# PRU_ICSS_CFG register map
Vendor: Texas Instruments
Peripheral module from a debugger description file (folder am437x).
Registers are 32-bit, access per field, no defined reset value unless marked. A register's access mark holds for its fields unless they carry their own. Offsets are as the file gives them; lines under a group give offsets from that group; [hi:lo] are bit positions; {n}, {i} and the like mark numbered series; 'fields as' and 'values as' point back to an identical list; <NAME> marks a mode.

## PRU_ICSS_CFG
0x00 PRU_ICSS_CFG_REVID ro — The Revision Register contains the ID and revision information.
  [31:0] REVID — Revision ID. Reset value for PRU-ICSS1 is 0x4700_0200 and for PRU-ICSS0 is 0x4701_0100.
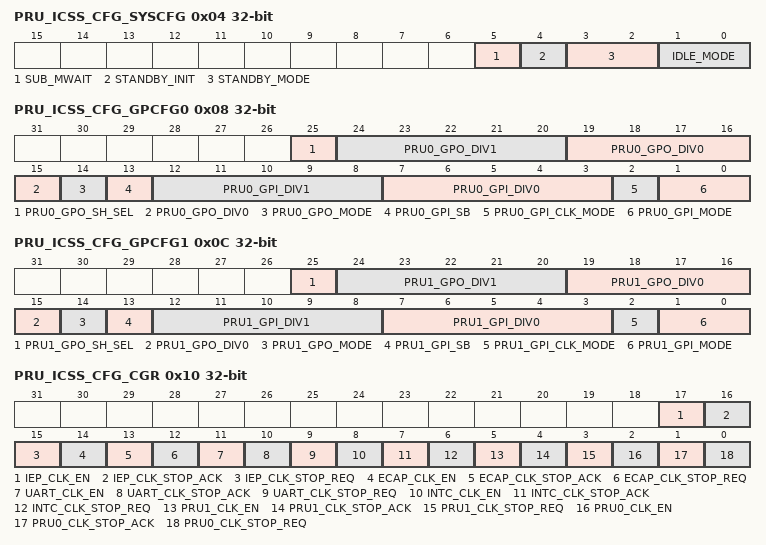
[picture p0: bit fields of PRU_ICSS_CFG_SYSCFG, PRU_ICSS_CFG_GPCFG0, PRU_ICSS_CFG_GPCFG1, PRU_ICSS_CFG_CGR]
0x04 PRU_ICSS_CFG_SYSCFG — The System Configuration Register defines the power IDLE and STANDBY modes. Note this register is only available for PRU-ICSS1. In PRU-ICSS0, it is reserved.
  [5] SUB_MWAIT ro — Status bit for wait state.
    1=en_2_0x1 (Wait until 0); 0=en_1_0x0 (Ready for Transaction)
  [4] STANDBY_INIT rw
    1=en_2_0x1 (Initiate standby sequence); 0=en_1_0x0 (Enable OCP master ports)
  [3:2] STANDBY_MODE rw
    3=en_4_0x3 (Reserved.); 2=en_3_0x2 (Smart standby mode: Standby requested by initiator depending on internal conditions.); 1=en_2_0x1 (No standby mode: Initiator unconditionally out of standby (standby = 0).); 0=en_1_0x0 (Force standby mode: Initiator unconditionally in standby (standby = 1).)
  [1:0] IDLE_MODE rw
    3=en_4_0x3 (Reserved.); 2=en_3_0x2 (Smart-idle mode.); 1=en_2_0x1 (No-idle mode.); 0=en_1_0x0 (Force-idle mode.)
0x08 PRU_ICSS_CFG_GPCFG0 — The General Purpose Configuration 0 Register defines the GPI/O configuration for PRU0.
  [25] PRU0_GPO_SH_SEL ro — Defines which shadow register is currently getting used for GPO shifting.
    1=en_2_0x1 (gpo_sh1 is selected); 0=en_1_0x0 (gpo_sh0 is selected)
  [24:20] PRU0_GPO_DIV1 rw — Divisor value (divide by PRU0_GPO_DIV1 + 1). 0h = div 1.0. 1h = div 1.5. 2h = div 2.0. .. 1eh = div 16.0. 1fh = reserved.
  [19:15] PRU0_GPO_DIV0 rw — Divisor value (divide by PRU0_GPO_DIV0 + 1). 0h = div 1.0. 1h = div 1.5. 2h = div 2.0. .. 1eh = div 16.0. 1fh = reserved.
  [14] PRU0_GPO_MODE rw
    1=en_2_0x1 (Serial output mode); 0=en_1_0x0 (Direct output mode)
  [13] PRU0_GPI_SB rw — Start Bit event for 28-bit shift mode. PRU0_GPI_SB (pru0_r31_status[29]) is set when first capture of a 1 on pru0_r31_status[0].
    1=en_4_0x1 (Will clear PRU0_GPI_SB and clear the whole shift register.); 1=en_3_0x1 (Start Bit event occurred.); 0=en_2_0x0 (No Effect.); 0=en_1_0x0 (Start Bit event has not occurred.)
  [12:8] PRU0_GPI_DIV1 rw — Divisor value (divide by PRU0_GPI_DIV1 + 1). 0h = div 1.0. 1h = div 1.5. 2h = div 2.0. .. 1eh = div 16.0. 1fh = reserved.
  [7:3] PRU0_GPI_DIV0 rw — Divisor value (divide by PRU0_GPI_DIV0 + 1). 0h = div 1.0. 1h = div 1.5. 2h = div 2.0. .. 1eh = div 16.0. 1fh = reserved.
  [2] PRU0_GPI_CLK_MODE rw — Parallel 16bit capture mode clock edge.
    1=en_2_0x1 (Use the negative edge of pru0_r31_status[16]); 0=en_1_0x0 (Use the positive edge of pru0_r31_status[16])
  [1:0] PRU0_GPI_MODE rw
0x0C PRU_ICSS_CFG_GPCFG1 — The General Purpose Configuration 1 Register defines the GPI/O configuration for PRU1.
  [25] PRU1_GPO_SH_SEL ro — Defines which shadow register is currently getting used for GPO shifting.
    values as PRU_ICSS_CFG_GPCFG0.PRU0_GPO_SH_SEL
  [24:20] PRU1_GPO_DIV1 rw — Divisor value (divide by PRU1_GPO_DIV1 + 1). 0h = div 1.0. 1h = div 1.5. 2h = div 2.0. .. 1eh = div 16.0. 1fh = reserved.
  [19:15] PRU1_GPO_DIV0 rw — Divisor value (divide by PRU1_GPO_DIV0 + 1). 0h = div 1.0. 1h = div 1.5. 2h = div 2.0. .. 1eh = div 16.0. 1fh = reserved.
  [14] PRU1_GPO_MODE rw
    values as PRU_ICSS_CFG_GPCFG0.PRU0_GPO_MODE
  [13] PRU1_GPI_SB rw — 28-bit shift mode Start Bit event. PRU1_GPI_SB (pru1_r31_status[29]) is set when first capture of a 1 on pru1_r31_status[0].
    1=en_4_0x1 (Will clear PRU1_GPI_SB and clear the whole shift register.); 1=en_3_0x1 (Start Bit event occurred.); 0=en_2_0x0 (No Effect.); 0=en_1_0x0 (Start Bit event has not occurred.)
  [12:8] PRU1_GPI_DIV1 rw — Divisor value (divide by PRU1_GPI_DIV1 + 1). 0h = div 1.0. 1h = div 1.5. 2h = div 2.0. .. 1eh = div 16.0. 1fh = reserved.
  [7:3] PRU1_GPI_DIV0 rw — Divisor value (divide by PRU1_GPI_DIV0 + 1). 0h = div 1.0. 1h = div 1.5. 2h = div 2.0. .. 1eh = div 16.0. 1fh = reserved.
  [2] PRU1_GPI_CLK_MODE rw — Parallel 16bit capture mode clock edge.
    1=en_2_0x1 (Use the negative edge of pru1_r31_status[16]); 0=en_1_0x0 (Use the positive edge of pru1_r31_status[16])
  [1:0] PRU1_GPI_MODE rw
0x10 PRU_ICSS_CFG_CGR — The Clock Gating Register controls the state of Clock Management of the different modules. Software should not clear {module}_CLK_EN until {module}_CLK_STOP_ACK is 0x1.
  [17] IEP_CLK_EN rw — IEP clock enable.
    1=en_2_0x1 (Enable Clock); 0=en_1_0x0 (Disable Clock)
  [16] IEP_CLK_STOP_ACK ro — Acknowledgement that IEP clock can be stopped.
    1=en_2_0x1 (Ready to Gate Clock); 0=en_1_0x0 (Not Ready to Gate Clock)
  [15] IEP_CLK_STOP_REQ rw — IEP request to stop clock.
    1=en_2_0x1 (Request to stop Clock); 0=en_1_0x0 (Do not request to stop Clock)
  [14] ECAP_CLK_EN rw — ECAP clock enable.
    1=en_2_0x1 (Enable Clock); 0=en_1_0x0 (Disable Clock)
  [13] ECAP_CLK_STOP_ACK ro — Acknowledgement that ECAP clock can be stopped.
    values as IEP_CLK_STOP_ACK
  [12] ECAP_CLK_STOP_REQ rw — ECAP request to stop clock.
    values as IEP_CLK_STOP_REQ
  [11] UART_CLK_EN rw — UART clock enable.
    1=en_2_0x1 (Enable Clock); 0=en_1_0x0 (Disable Clock)
  [10] UART_CLK_STOP_ACK ro — Acknowledgement that UART clock can be stopped.
    values as IEP_CLK_STOP_ACK
  [9] UART_CLK_STOP_REQ rw — UART request to stop clock.
    values as IEP_CLK_STOP_REQ
  [8] INTC_CLK_EN rw — INTC clock enable.
    1=en_2_0x1 (Enable Clock); 0=en_1_0x0 (Disable Clock)
  [7] INTC_CLK_STOP_ACK ro — Acknowledgement that INTC clock can be stopped.
    values as IEP_CLK_STOP_ACK
  [6] INTC_CLK_STOP_REQ rw — INTC request to stop clock.
    values as IEP_CLK_STOP_REQ
  [5] PRU1_CLK_EN rw — PRU1 clock enable.
    1=en_2_0x1 (Enable Clock); 0=en_1_0x0 (Disable Clock)
  [4] PRU1_CLK_STOP_ACK ro — Acknowledgement that PRU1 clock can be stopped.
    values as IEP_CLK_STOP_ACK
  [3] PRU1_CLK_STOP_REQ rw — PRU1 request to stop clock.
    values as IEP_CLK_STOP_REQ
  [2] PRU0_CLK_EN rw — PRU0 clock enable.
    1=en_2_0x1 (Enable Clock); 0=en_1_0x0 (Disable Clock)
  [1] PRU0_CLK_STOP_ACK ro — Acknowledgement that PRU0 clock can be stopped.
    values as IEP_CLK_STOP_ACK
  [0] PRU0_CLK_STOP_REQ rw — PRU0 request to stop clock.
    values as IEP_CLK_STOP_REQ
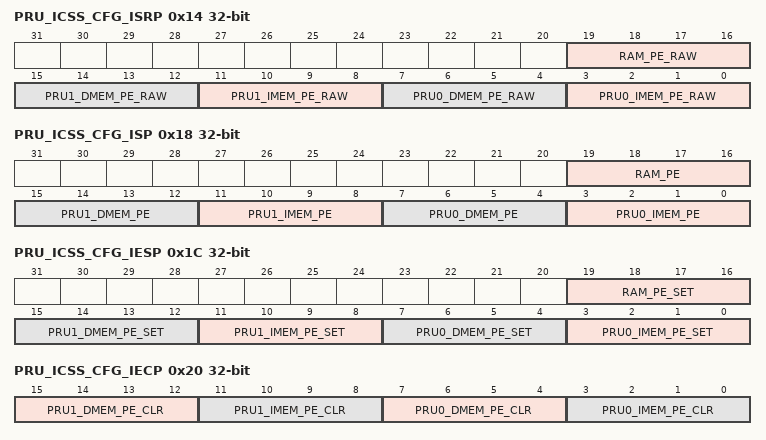
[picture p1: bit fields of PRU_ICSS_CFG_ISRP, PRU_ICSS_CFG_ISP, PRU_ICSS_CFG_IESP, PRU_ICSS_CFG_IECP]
0x14 PRU_ICSS_CFG_ISRP — The IRQ Status Raw Parity register is a snapshot of the IRQ raw status for the PRU ICSS memory parity events. The raw status is set even if the event is not enabled.
  [all] fields
    1=en_4_0x1 (Event pending); 1=en_3_0x1 (Set event (debug)); 0=en_2_0x0 (No event pending); 0=en_1_0x0 (No action)
  [19:16] RAM_PE_RAW rw — PRU-ICSS1 Only. RAM Parity Error RAW for Byte3, Byte2, Byte1, Byte0. Note RAM_PE_RAW[0] maps to Byte0.
  [15:12] PRU1_DMEM_PE_RAW rw — PRU1 DMEM Parity Error RAW for Byte3, Byte2, Byte1, Byte0. Note PRU1_DMEM_PE_RAW[0] maps to Byte0.
  [11:8] PRU1_IMEM_PE_RAW rw — PRU1 IMEM Parity Error RAW for Byte3, Byte2, Byte1, Byte0. Note PRU1_IMEM_PE_RAW[0] maps to Byte0.
  [7:4] PRU0_DMEM_PE_RAW rw — PRU0 DMEM Parity Error RAW for Byte3, Byte2, Byte1, Byte0. Note PRU0_DMEM_PE_RAW[0] maps to Byte0.
  [3:0] PRU0_IMEM_PE_RAW rw — PRU0 IMEM Parity Error RAW for Byte3, Byte2, Byte1, Byte0. Note PRU0_IRAM_PE_RAW[0] maps to Byte0.
0x18 PRU_ICSS_CFG_ISP access not given — The IRQ Status Parity Register is a snapshot of the IRQ status for the PRU ICSS memory parity events. The status is set only if the event is enabled. Write 1 to clear the status after the interrupt has been serviced.
  [all] fields
    1=en_4_0x1 (Event pending); 1=en_3_0x1 (Clear event); 0=en_2_0x0 (No (enabled) event pending); 0=en_1_0x0 (No action)
  [19:16] RAM_PE — PRU-ICSS1 Only. RAM Parity Error for Byte3, Byte2, Byte1, Byte0. Note RAM_PE[0] maps to Byte0.
  [15:12] PRU1_DMEM_PE — PRU1 DMEM Parity Error for Byte3, Byte2, Byte1, Byte0. Note PRU1_DMEM_PE[0] maps to Byte0.
  [11:8] PRU1_IMEM_PE — PRU1 IMEM Parity Error for Byte3, Byte2, Byte1, Byte0. Note PRU1_IMEM_PE[0] maps to Byte0.
  [7:4] PRU0_DMEM_PE — PRU0 DMEM Parity Error for Byte3, Byte2, Byte1, Byte0. Note PRU0_DMEM_PE[0] maps to Byte0.
  [3:0] PRU0_IMEM_PE — PRU0 IMEM Parity Error for Byte3, Byte2, Byte1, Byte0. Note PRU0_IMEM_PE[0] maps to Byte0.
0x1C PRU_ICSS_CFG_IESP — The IRQ Enable Set Parity Register enables the IRQ PRU ICSS memory parity events.
  [all] fields
    1=en_4_0x1 (Enable interrupt); 1=en_3_0x1 (Interrupt enabled); 0=en_2_0x0 (Interrupt disabled (masked)); 0=en_1_0x0 (No action)
  [19:16] RAM_PE_SET rw — PRU-ICSS1 Only. RAM Parity Error Set Enable for Byte3, Byte2, Byte1, Byte0. Note RAM_PE_SET[0] maps to Byte0.
  [15:12] PRU1_DMEM_PE_SET rw — PRU1 DMEM Parity Error Set Enable for Byte3, Byte2, Byte1, Byte0. Note PRU1_DMEM_PE_SET[0] maps to Byte0.
  [11:8] PRU1_IMEM_PE_SET rw — PRU1 IMEM Parity Error Set Enable for Byte3, Byte2, Byte1, Byte0. Note PRU1_IMEM_PE_SET[0] maps to Byte0.
  [7:4] PRU0_DMEM_PE_SET rw — PRU0 DMEM Parity Error Set Enable for Byte3, Byte2, Byte1, Byte0. Note PRU0_DMEM_PE_SET[0] maps to Byte0.
  [3:0] PRU0_IMEM_PE_SET rw — PRU0 IMEM Parity Error Set Enable for Byte3, Byte2, Byte1, Byte0. Note PRU0_IMEM_PE_SET[0] maps to Byte0.
0x20 PRU_ICSS_CFG_IECP — The IRQ Enable Clear Parity Register disables the IRQ PRU ICSS memory parity events.
  [all] fields
    1=en_4_0x1 (Interrupt enabled); 1=en_3_0x1 (Disable interrupt); 0=en_2_0x0 (Interrupt disabled (masked)); 0=en_1_0x0 (No action)
  [15:12] PRU1_DMEM_PE_CLR rw — PRU1 DMEM Parity Error Clear Enable for Byte3, Byte2, Byte1, Byte0. Note PRU1_DMEM_PE_CLR[0] maps to Byte0.
  [11:8] PRU1_IMEM_PE_CLR rw — PRU1 IMEM Parity Error Clear Enable for Byte3, Byte2, Byte1, Byte0. Note PRU1_IMEM_PE_CLR[0] maps to Byte0.
  [7:4] PRU0_DMEM_PE_CLR rw — PRU0 DMEM Parity Error Clear Enable for Byte3, Byte2, Byte1, Byte0. Note PRU0_DMEM_PE_CLR[0] maps to Byte0.
  [3:0] PRU0_IMEM_PE_CLR rw — PRU0 IMEM Parity Error Clear Enable for Byte3, Byte2, Byte1, Byte0. Note PRU0_IMEM_PE_CLR[0] maps to Byte0.
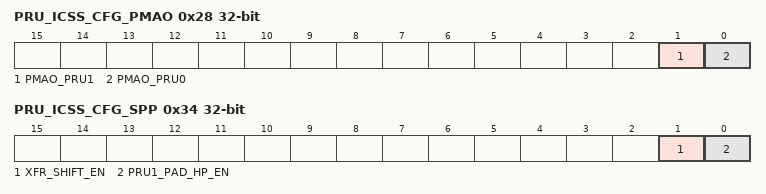
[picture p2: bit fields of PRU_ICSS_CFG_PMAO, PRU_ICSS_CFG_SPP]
0x28 PRU_ICSS_CFG_PMAO — The PRU Master OCP Address Offset Register enables for the PRU OCP Master Port Address to have an offset of minus 0x0008_0000. This enables the PRU to access External Host address space starting at 0x0000_0000.
  [1] PMAO_PRU1 rw — PRU1 OCP Master Port Address Offset Enable.
    1=en_2_0x1 (Enable address offset of -0x0008_0000.); 0=en_1_0x0 (Disable address offset.)
  [0] PMAO_PRU0 rw — PRU0 OCP Master Port Address Offset Enable.
    values as PMAO_PRU1
0x30 PRU_ICSS_CFG_IEPCLK — The IEP Clock Source Register defines the source of the IEP clock.
  [0] OCP_EN rw
    1=en_2_0x1 (ocp_clk is the source); 0=en_1_0x0 (iep_clk is the source)
0x34 PRU_ICSS_CFG_SPP — The Scratch Pad Priority and Configuration Register defines the access priority assigned to the PRU cores and configures the scratch pad XFR shift functionality.
  [1] XFR_SHIFT_EN rw — Enables XIN/XOUT shift functionality. When enabled, R0 [4:0] (internal to PRU) defines the 32-bit offset for XIN and XOUT operations with the scratch pad.
    1=en_2_0x1 (Enabled); 0=en_1_0x0 (Disabled)
  [0] PRU1_PAD_HP_EN rw — Defines which PRU wins write cycle arbitration to a common scratch pad bank. The PRU which has higher priority will always perform the write cycle with no wait states. The lower PRU will get stalled/wait states until higher PRU is not performing write cycles. If the lower priority PRU writes to the same byte has the higher priority PRU, then the lower priority PRU will over write the bytes.
    1=en_2_0x1 (PRU1 has highest priority); 0=en_1_0x0 (PRU0 has highest priority)
0x40 PRU_ICSS_CFG_PIN_MX — The Pin Mux Select Register defines the state of the PRU ICSS internal pinmuxing.
  [7:0] PIN_MUX_SEL rw — Defines the state of PIN_MUX_SEL [1:0] for internal pinmuxing.
